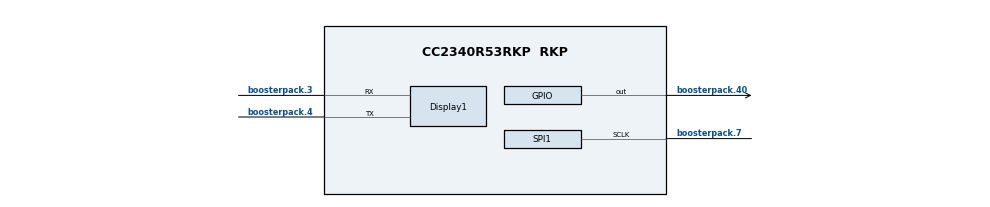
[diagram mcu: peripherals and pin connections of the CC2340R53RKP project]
/**
 * @cliArgs --board "/ti/boards/LP_EM_CC2340R53" --device "CC2340R53RKP" --part "Default" --package "RKP" --rtos "freertos" --product "simplelink_lowpower_f3_sdk@9.14.02.16"
 * @versions {"tool":"1.23.2+4156"}
 */

/**
 * Import the modules used in this configuration.
 */
const FreeRTOS    = scripting.addModule("/freertos/FreeRTOS");
const ble         = scripting.addModule("/ti/ble/ble");
const CCFG        = scripting.addModule("/ti/devices/CCFG");
const rfdesign    = scripting.addModule("/ti/devices/radioconfig/rfdesign");
const Display     = scripting.addModule("/ti/display/Display");
const Display1    = Display.addInstance();
const ADCBuf      = scripting.addModule("/ti/drivers/ADCBuf", {}, false);
const ADCBuf1     = ADCBuf.addInstance();
const AESCCM      = scripting.addModule("/ti/drivers/AESCCM");
const AESCCM1     = AESCCM.addInstance();
const AESCTRDRBG  = scripting.addModule("/ti/drivers/AESCTRDRBG");
const AESCTRDRBG1 = AESCTRDRBG.addInstance();
const AESECB      = scripting.addModule("/ti/drivers/AESECB");
const AESECB1     = AESECB.addInstance();
const ECDH        = scripting.addModule("/ti/drivers/ECDH");
const ECDH1       = ECDH.addInstance();
const GPIO        = scripting.addModule("/ti/drivers/GPIO");
const GPIO2       = GPIO.addInstance();
const GPIO3       = GPIO.addInstance();
const GPIO4       = GPIO.addInstance();
const NVS         = scripting.addModule("/ti/drivers/NVS");
const NVS1        = NVS.addInstance();
const Power       = scripting.addModule("/ti/drivers/Power");
const RCL         = scripting.addModule("/ti/drivers/RCL");
const RNG         = scripting.addModule("/ti/drivers/RNG");
const RNG1        = RNG.addInstance();
const SPI         = scripting.addModule("/ti/drivers/SPI", {}, false);
const SPI1        = SPI.addInstance();
const Button      = scripting.addModule("/ti/drivers/apps/Button", {}, false);
const Button1     = Button.addInstance();
const Button2     = Button.addInstance();
const Settings    = scripting.addModule("/ti/posix/freertos/Settings");

/**
 * Write custom configuration values to the imported modules.
 */
FreeRTOS.heapSize       = 0x00004D50;
FreeRTOS.timerStackSize = 0x00000190;
FreeRTOS.idleStackSize  = 0x00000130;

ble.basicBLE                                          = true;
ble.disDevBySerUuid                                   = true;
ble.deviceName                                        = "Basic BLE project";
ble.numOfAdvSets                                      = 1;
ble.connIntMin                                        = 1000;
ble.connIntMax                                        = 1000;
ble.defaultTxPowerValue                               = "8";
ble.addressMode                                       = "ADDRMODE_PUBLIC";
ble.maxPDUNum                                         = 255;
ble.maxPDUSize                                        = 255;
ble.disableDisplayModule                              = true;
ble.radioConfig.codeExportConfig.$name                = "ti_devices_radioconfig_code_export_param0";
ble.adcNoiseConfig.codeExportConfig.$name             = "ti_devices_radioconfig_code_export_param1";
ble.bleCsConfig.codeExportConfig.$name                = "ti_devices_radioconfig_code_export_param2";
ble.connUpdateParamsPeripheral.$name                  = "ti_ble_general_ble_conn_update_params0";
ble.advSet1.$name                                     = "ti_ble_broadcaster_advertisement_set0";
ble.advSet1.advParam1.$name                           = "ti_ble_broadcaster_advertisement_params0";
ble.advSet1.advData1.$name                            = "ti_ble_broadcaster_advertisement_data0";
ble.advSet1.advData1.GAP_ADTYPE_16BIT_MORE            = true;
ble.advSet1.advData1.numOfUUIDs16More                 = 1;
ble.advSet1.advData1.UUID016More                      = 0xFFF0;
ble.advSet1.advData1.GAP_ADTYPE_128BIT_MORE           = true;
ble.advSet1.advData1.numOfUUIDs128More                = 1;
ble.advSet1.advData1.UUID0128More                     = system.utils.bigInt("B000405104C0C000F0",16);
ble.advSet1.advData1.GAP_ADTYPE_MANUFACTURER_SPECIFIC = true;
ble.advSet1.scanRes1.$name                            = "ti_ble_broadcaster_advertisement_data1";

CCFG.ccfgTemplate.$name = "ti_devices_CCFG_CCFGCC23X0Template0";

Display1.$name                                        = "CONFIG_Display_0";
Display1.enableANSI                                   = true;
Display1.uartBufferSize                               = 128;
Display1.uart.$name                                   = "CONFIG_UART2_0";
Display1.uart.uart.dmaRxChannel.$assignAllowConflicts = "DMA_CH0";
Display1.uart.uart.txPin.$assign                      = "boosterpack.4";
Display1.uart.uart.rxPin.$assign                      = "boosterpack.3";

ADCBuf1.$name                      = "CONFIG_ADCBUF_0";
ADCBuf1.adc.dataDmaChannel.$assign = "DMA_CH3";
ADCBuf1.adcChannels[0].$name       = "CONFIG_ADC_CHANNEL_0";

AESCCM1.$name = "CONFIG_AESCCM0";

AESCTRDRBG1.$name = "CONFIG_AESCTRDRBG_0";

AESECB1.$name = "CONFIG_AESECB0";

ECDH1.$name = "CONFIG_ECDH0";

GPIO2.$hardware       = system.deviceData.board.components.LED_GREEN;
GPIO2.$name           = "CONFIG_GPIO_LED_GREEN";
GPIO2.gpioPin.$assign = "boosterpack.40";

GPIO3.$hardware = system.deviceData.board.components.LED_RED;
GPIO3.$name     = "CONFIG_GPIO_LED_RED";

GPIO4.$name = "CONFIG_GPIO_MIC";

NVS1.$name                    = "CONFIG_NVSINTERNAL";
NVS1.internalFlash.$name      = "ti_drivers_nvs_NVSLPF30";
NVS1.internalFlash.regionBase = 0x7D000;
NVS1.internalFlash.regionSize = 0x3000;

RNG.rngReturnBehavior = "RNG_RETURN_BEHAVIOR_BLOCKING";

RNG1.$name = "CONFIG_RNG_0";

SPI1.$name                                  = "CONFIG_SPI_0";
SPI1.minDmaTransferSize                     = 32;
SPI1.spi.sclkPin.$assign                    = "boosterpack.7";
SPI1.spi.dmaTxChannel.$assignAllowConflicts = "DMA_CH0";

Button1.$name     = "CONFIG_BUTTON_0";
Button1.$hardware = system.deviceData.board.components["BTN-1"];

Button2.$name     = "CONFIG_BUTTON_1";
Button2.$hardware = system.deviceData.board.components["BTN-2"];

/**
 * Pinmux solution for unlocked pins/peripherals. This ensures that minor changes to the automatic solver in a future
 * version of the tool will not impact the pinmux you originally saw.  These lines can be completely deleted in order to
 * re-solve from scratch.
 */
Display1.uart.uart.$suggestSolution                = "UART0";
Display1.uart.uart.dmaTxChannel.$suggestSolution   = "DMA_CH2";
ADCBuf1.adc.$suggestSolution                       = "ADC";
ADCBuf1.adcChannels[0].adc.$suggestSolution        = "ADC";
ADCBuf1.adcChannels[0].adc.adcPin.$suggestSolution = "boosterpack.28";
GPIO3.gpioPin.$suggestSolution                     = "boosterpack.39";
GPIO4.gpioPin.$suggestSolution                     = "boosterpack.36";
SPI1.spi.$suggestSolution                          = "SPI0";
SPI1.spi.dmaRxChannel.$suggestSolution             = "DMA_CH1";
SPI1.spi.pociPin.$suggestSolution                  = "boosterpack.37";
SPI1.spi.picoPin.$suggestSolution                  = "boosterpack.17";
Button1.button.$suggestSolution                    = "boosterpack.13";
Button2.button.$suggestSolution                    = "boosterpack.12";
